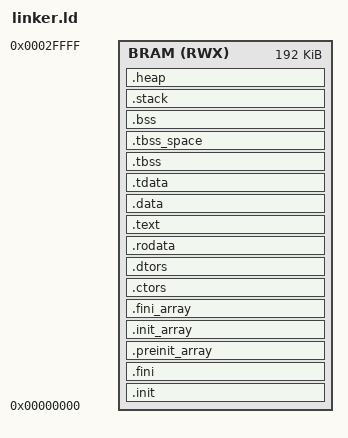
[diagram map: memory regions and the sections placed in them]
ENTRY(_enter)

MEMORY
{
   BRAM (RWX) : ORIGIN = 0x0000, LENGTH = 0x30000 /* 192k */
}

SECTIONS
{
    __stack_size = 0x1000;
    __heap_size = 0x1000;

    /* ROM SECTION
     *
     * The following sections contain data which lives in read-only memory, if
     * such memory is present in the design, for the entire duration of program
     * execution.
     */

    .init : {
        /* The _enter symbol is placed in the .text.metal.init.enter section
         * and must be placed at the beginning of the program */
        KEEP (*(.text.init.enter))
    } >BRAM

    .fini : {
        KEEP (*(SORT_NONE(.fini)))
    } >BRAM

    .preinit_array : ALIGN(8) {
        PROVIDE_HIDDEN (__preinit_array_start = .);
        KEEP (*(.preinit_array))
        PROVIDE_HIDDEN (__preinit_array_end = .);
    } >BRAM

    .init_array : ALIGN(8) {
        PROVIDE_HIDDEN (__init_array_start = .);
        KEEP (*(SORT_BY_INIT_PRIORITY(.init_array.*) SORT_BY_INIT_PRIORITY(.ctors.*)))
        KEEP (*(.init_array EXCLUDE_FILE (*crtbegin.o *crtbegin?.o *crtend.o *crtend?.o ) .ctors))
        PROVIDE_HIDDEN (__init_array_end = .);
        PROVIDE_HIDDEN ( metal_constructors_start = .);
        KEEP (*(SORT_BY_INIT_PRIORITY(.metal.init_array.*)));
        KEEP (*(.metal.init_array));
        PROVIDE_HIDDEN ( metal_constructors_end = .);
    } >BRAM

    .fini_array : ALIGN(8) {
        PROVIDE_HIDDEN (__fini_array_start = .);
        KEEP (*(SORT_BY_INIT_PRIORITY(.fini_array.*) SORT_BY_INIT_PRIORITY(.dtors.*)))
        KEEP (*(.fini_array EXCLUDE_FILE (*crtbegin.o *crtbegin?.o *crtend.o *crtend?.o ) .dtors))
        PROVIDE_HIDDEN (__fini_array_end = .);
        PROVIDE_HIDDEN ( metal_destructors_start = .);
        KEEP (*(SORT_BY_INIT_PRIORITY(.metal.fini_array.*)));
        KEEP (*(.metal.fini_array));
        PROVIDE_HIDDEN ( metal_destructors_end = .);
    } >BRAM

    .ctors : {
        KEEP (*crtbegin.o(.ctors))
        KEEP (*crtbegin?.o(.ctors))
        KEEP (*(EXCLUDE_FILE (*crtend.o *crtend?.o ) .ctors))
        KEEP (*(SORT(.ctors.*)))
        KEEP (*(.ctors))
        KEEP (*(.metal.ctors .metal.ctors.*))
    } >BRAM

    .dtors : {
        KEEP (*crtbegin.o(.dtors))
        KEEP (*crtbegin?.o(.dtors))
        KEEP (*(EXCLUDE_FILE (*crtend.o *crtend?.o ) .dtors))
        KEEP (*(SORT(.dtors.*)))
        KEEP (*(.dtors))
        KEEP (*(.metal.dtors .metal.dtors.*))
    } >BRAM

    .rodata : {
        *(.rdata)
        *(.rodata .rodata.*)
        *(.gnu.linkonce.r.*)
        . = ALIGN(8);
        *(.srodata.cst16)
        *(.srodata.cst8)
        *(.srodata.cst4)
        *(.srodata.cst2)
        *(.srodata .srodata.*)
    } >BRAM

    /* TEXT SECTION
     *
     * The following section contains the code of the program, excluding
     * everything that's been allocated into the ITIM/LIM already
     */

    .text : {
        *(.text.unlikely .text.unlikely.*)
        *(.text.startup .text.startup.*)
        *(.text .text.*)
        *(.gnu.linkonce.t.*)
    } >BRAM

    /* RAM SECTION
     *
     * The following sections contain data which is copied from read-only
     * memory into a read-write-capable memory such as data tightly-integrated
     * memory (DTIM) or another main memory, as well as the BSS, stack, and
     * heap.
     *
     * You might notice that .data, .tdata, .tbss, .tbss_space, and .bss all
     * have an apparently unnecessary ALIGN at their top. This is because
     * the implementation of _start in Freedom Metal libgloss depends on the
     * ADDR and LOADADDR being 8-byte aligned.
     */

    .data : ALIGN(8) {
        *(.data .data.*)
        *(.gnu.linkonce.d.*)
        . = ALIGN(8);
        PROVIDE( __global_pointer$ = . + 0x800 );
        *(.sdata .sdata.* .sdata2.*)
        *(.gnu.linkonce.s.*)
    } >BRAM

    .tdata : ALIGN(8) {
        PROVIDE( __tls_base = . );
	    *(.tdata .tdata.* .gnu.linkonce.td.*)
    } >BRAM

    PROVIDE( __tdata_source = LOADADDR(.tdata) );
    PROVIDE( __tdata_size = SIZEOF(.tdata) );

    PROVIDE( data_source_start = LOADADDR(.data) );
    PROVIDE( data_target_start = ADDR(.data) );
    PROVIDE( data_target_end = ADDR(.tdata) + SIZEOF(.tdata) );

    .tbss : ALIGN(8) {
	    *(.tbss .tbss.* .gnu.linkonce.tb.*)
	    *(.tcommon .tcommon.*)
	    PROVIDE( __tls_end = . );
    } >BRAM
    PROVIDE( __tbss_size = SIZEOF(.tbss) );
    PROVIDE( __tls_size = __tls_end - __tls_base );

    .tbss_space : ALIGN(8) {
	    . = . + __tbss_size;
    } >BRAM

    .bss (NOLOAD): ALIGN(8) {
        *(.sbss*)
        *(.gnu.linkonce.sb.*)
        *(.bss .bss.*)
        *(.gnu.linkonce.b.*)
        *(COMMON)
    } >BRAM

    PROVIDE( bss_source_start = LOADADDR(.tbss) );
    PROVIDE( bss_target_start = ADDR(.tbss) );
    PROVIDE( bss_target_end = ADDR(.bss) + SIZEOF(.bss) );

    .stack (NOLOAD) : ALIGN(16) {
        PROVIDE(stack_begin = .);
        . += __stack_size; /* Hart 0 */
        PROVIDE( _sp = . );
        PROVIDE(stack_end = .);
    } >BRAM

    .heap (NOLOAD) : ALIGN(8) {
        PROVIDE( __heap_start = . );
        PROVIDE( heap_target_start = . );
        /* If __heap_max is defined, grow the heap to use the rest of RAM,
         * otherwise set the heap size to __heap_size */
        . = DEFINED(__heap_max) ? MIN( LENGTH(ram) - ( . - ORIGIN(ram)) , 0x10000000) : __heap_size;
        PROVIDE( heap_target_end = . );
        PROVIDE( _heap_end = . );
        PROVIDE( __heap_end = . );
    } >BRAM

    /* C++ exception handling information is
     * not useful with our current runtime environment,
     * and it consumes flash space. Discard it until
     * we have something that can use it
     */
    /DISCARD/ : {
	*(.eh_frame .eh_frame.* .gcc_except_table.*)
    }
}
